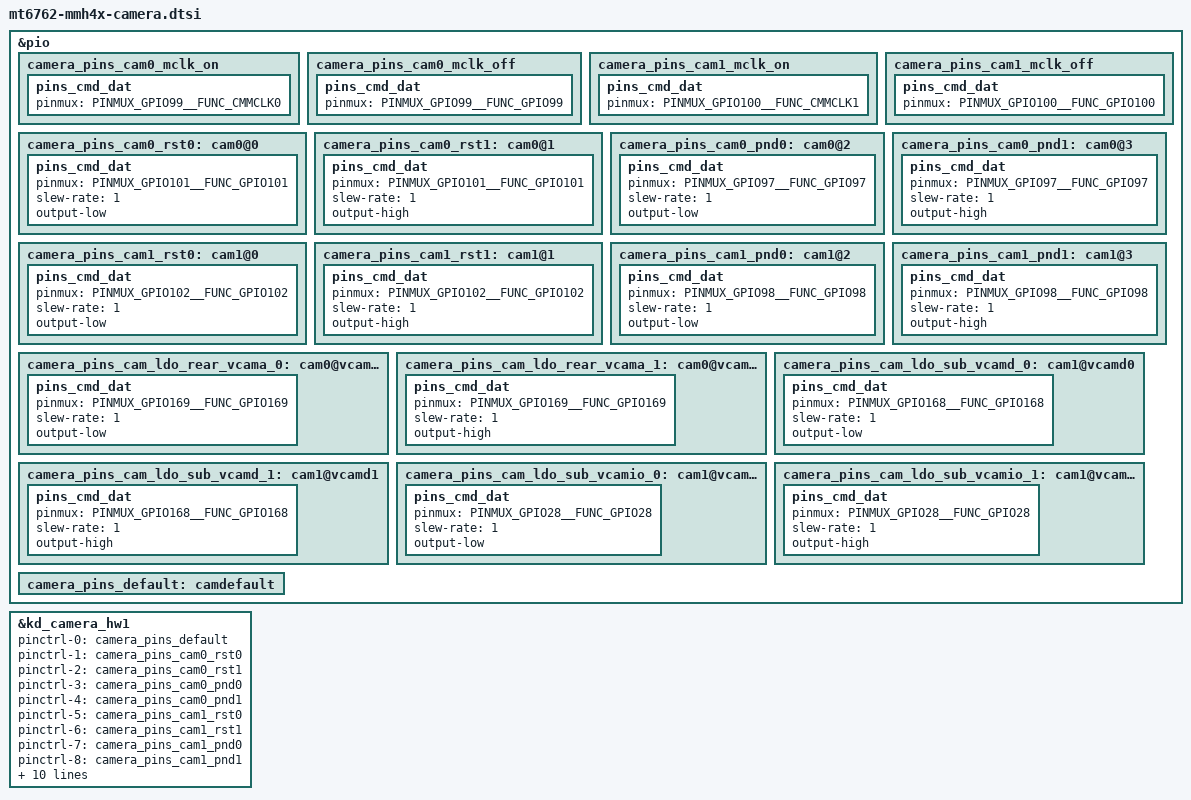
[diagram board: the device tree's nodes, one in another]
/*
 * LG Electronics MT6765 HDK camera device tree source
 *
 * Copyright (c) 2018 LG Electronics Co., Ltd.
 *              http://www.lge.com
 *
 */

&pio {
	camera_pins_cam0_mclk_on: camera_pins_cam0_mclk_on {
		pins_cmd_dat {
			pinmux = <PINMUX_GPIO99__FUNC_CMMCLK0>;
		};
	};
	camera_pins_cam0_mclk_off: camera_pins_cam0_mclk_off {
		pins_cmd_dat {
			pinmux = <PINMUX_GPIO99__FUNC_GPIO99>;
		};
	};
	camera_pins_cam1_mclk_on: camera_pins_cam1_mclk_on {
		pins_cmd_dat {
			pinmux = <PINMUX_GPIO100__FUNC_CMMCLK1>;
		};
	};
	camera_pins_cam1_mclk_off: camera_pins_cam1_mclk_off {
		pins_cmd_dat {
			pinmux = <PINMUX_GPIO100__FUNC_GPIO100>;
		};
	};
	camera_pins_cam0_rst0: cam0@0 {
		pins_cmd_dat {
			pinmux = <PINMUX_GPIO101__FUNC_GPIO101>;
			slew-rate = <1>;
			output-low;
		};
	};
	camera_pins_cam0_rst1: cam0@1 {
		pins_cmd_dat {
			pinmux = <PINMUX_GPIO101__FUNC_GPIO101>;
			slew-rate = <1>;
			output-high;
		};
	};
	camera_pins_cam0_pnd0: cam0@2 {
		pins_cmd_dat {
			pinmux = <PINMUX_GPIO97__FUNC_GPIO97>;
			slew-rate = <1>;
			output-low;
		};
	};
	camera_pins_cam0_pnd1: cam0@3 {
		pins_cmd_dat {
			pinmux = <PINMUX_GPIO97__FUNC_GPIO97>;
			slew-rate = <1>;
			output-high;
		};
	};
	camera_pins_cam1_rst0: cam1@0 {
		pins_cmd_dat {
			pinmux = <PINMUX_GPIO102__FUNC_GPIO102>;
			slew-rate = <1>;
			output-low;
		};
	};
	camera_pins_cam1_rst1: cam1@1 {
		pins_cmd_dat {
			pinmux = <PINMUX_GPIO102__FUNC_GPIO102>;
			slew-rate = <1>;
			output-high;
		};
	};
	camera_pins_cam1_pnd0: cam1@2 {
		pins_cmd_dat {
			pinmux = <PINMUX_GPIO98__FUNC_GPIO98>;
			slew-rate = <1>;
			output-low;
		};
	};
	camera_pins_cam1_pnd1: cam1@3 {
		pins_cmd_dat {
			pinmux = <PINMUX_GPIO98__FUNC_GPIO98>;
			slew-rate = <1>;
			output-high;
		};
	};
	camera_pins_cam_ldo_rear_vcama_0: cam0@vcama0 {
		pins_cmd_dat {
			pinmux = <PINMUX_GPIO169__FUNC_GPIO169>;
			slew-rate = <1>;
			output-low;
		};
	};
	camera_pins_cam_ldo_rear_vcama_1: cam0@vcama1 {
		pins_cmd_dat {
			pinmux = <PINMUX_GPIO169__FUNC_GPIO169>;
			slew-rate = <1>;
			output-high;
		};
	};
	camera_pins_cam_ldo_sub_vcamd_0: cam1@vcamd0 {
		pins_cmd_dat {
			pinmux = <PINMUX_GPIO168__FUNC_GPIO168>;
			slew-rate = <1>;
			output-low;
		};
	};
	camera_pins_cam_ldo_sub_vcamd_1: cam1@vcamd1 {
		pins_cmd_dat {
			pinmux = <PINMUX_GPIO168__FUNC_GPIO168>;
			slew-rate = <1>;
			output-high;
		};
	};
	camera_pins_cam_ldo_sub_vcamio_0: cam1@vcamio0 {
		pins_cmd_dat {
			pinmux = <PINMUX_GPIO28__FUNC_GPIO28>;
			slew-rate = <1>;
			output-low;
		};
	};
	camera_pins_cam_ldo_sub_vcamio_1: cam1@vcamio1 {
		pins_cmd_dat {
			pinmux = <PINMUX_GPIO28__FUNC_GPIO28>;
			slew-rate = <1>;
			output-high;
		};
	};
	camera_pins_default: camdefault {
	};

};

&kd_camera_hw1 {
	pinctrl-names = "default",
			"cam0_rst0",
			"cam0_rst1",
			"cam0_pnd0",
			"cam0_pnd1",
			"cam1_rst0",
			"cam1_rst1",
			"cam1_pnd0",
			"cam1_pnd1",
			"cam0_vcama_on",
			"cam0_vcama_off",
			"cam1_vcamd_on",
			"cam1_vcamd_off",
			"cam1_vcamio_on",
			"cam1_vcamio_off",
			"cam0_mclk_on",
			"cam0_mclk_off",
			"cam1_mclk_on",
			"cam1_mclk_off";

	pinctrl-0 = <&camera_pins_default>;
	pinctrl-1 = <&camera_pins_cam0_rst0>;
	pinctrl-2 = <&camera_pins_cam0_rst1>;
	pinctrl-3 = <&camera_pins_cam0_pnd0>;
	pinctrl-4 = <&camera_pins_cam0_pnd1>;
	pinctrl-5 = <&camera_pins_cam1_rst0>;
	pinctrl-6 = <&camera_pins_cam1_rst1>;
	pinctrl-7 = <&camera_pins_cam1_pnd0>;
	pinctrl-8 = <&camera_pins_cam1_pnd1>;
	pinctrl-9 = <&camera_pins_cam_ldo_rear_vcama_1>;
	pinctrl-10 = <&camera_pins_cam_ldo_rear_vcama_0>;
	pinctrl-11 = <&camera_pins_cam_ldo_sub_vcamd_1>;
	pinctrl-12 = <&camera_pins_cam_ldo_sub_vcamd_0>;
	pinctrl-13 = <&camera_pins_cam_ldo_sub_vcamio_1>;
	pinctrl-14 = <&camera_pins_cam_ldo_sub_vcamio_0>;
	pinctrl-15 = <&camera_pins_cam0_mclk_on>;
	pinctrl-16 = <&camera_pins_cam0_mclk_off>;
	pinctrl-17 = <&camera_pins_cam1_mclk_on>;
	pinctrl-18 = <&camera_pins_cam1_mclk_off>;
	status = "okay";

};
